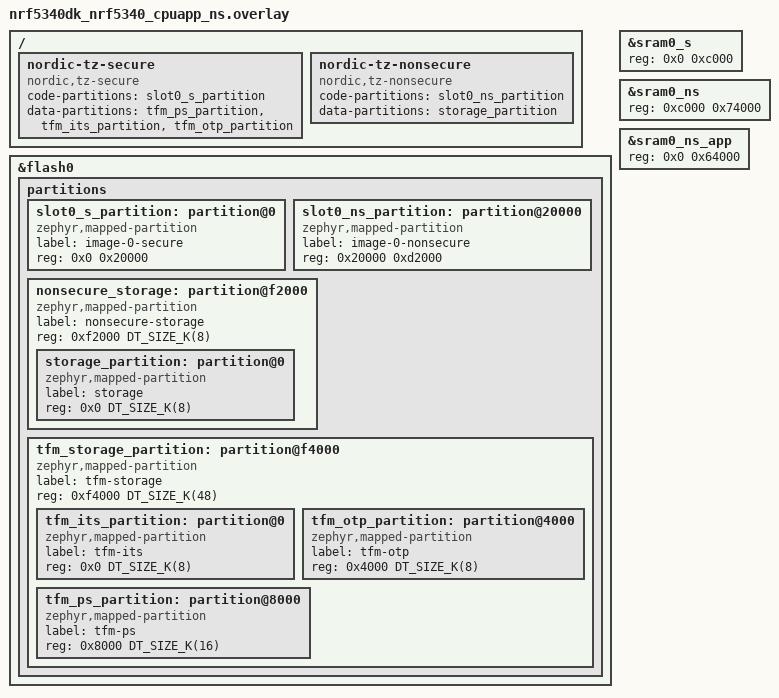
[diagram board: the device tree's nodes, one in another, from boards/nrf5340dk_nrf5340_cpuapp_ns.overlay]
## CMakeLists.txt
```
#
# Copyright (c) 2021 Nordic Semiconductor
#
# SPDX-License-Identifier: LicenseRef-Nordic-5-Clause
#

cmake_minimum_required(VERSION 3.20.0)

find_package(Zephyr REQUIRED HINTS $ENV{ZEPHYR_BASE})
project(NONE)

target_sources(app  PRIVATE src/main.c)
```

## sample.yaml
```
sample:
  description: NFC Launch App sample
  name: NFC Launch App
tests:
  sample.nfc.launch_app:
    sysbuild: true
    build_only: true
    integration_platforms:
      - nrf52840dk/nrf52840
      - nrf5340dk/nrf5340/cpuapp
      - nrf5340dk/nrf5340/cpuapp/ns
      - nrf54h20dk/nrf54h20/cpuapp
      - nrf54l15dk/nrf54l05/cpuapp
      - nrf54l15dk/nrf54l10/cpuapp
      - nrf54l15dk/nrf54l15/cpuapp
      - nrf54lm20dk/nrf54lm20a/cpuapp
      - nrf7120dk/nrf7120/cpuapp
    platform_allow:
      - nrf52840dk/nrf52840
      - nrf52dk/nrf52832
      - nrf5340dk/nrf5340/cpuapp
      - nrf5340dk/nrf5340/cpuapp/ns
      - nrf54h20dk/nrf54h20/cpuapp
      - nrf54l15dk/nrf54l05/cpuapp
      - nrf54l15dk/nrf54l10/cpuapp
      - nrf54l15dk/nrf54l15/cpuapp
      - nrf54lm20dk/nrf54lm20a/cpuapp
      - nrf7120dk/nrf7120/cpuapp
    tags:
      - ci_build
      - sysbuild
      - ci_samples_nfc
```

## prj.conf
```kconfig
#
# Copyright (c) 2021 Nordic Semiconductor ASA
#
# SPDX-License-Identifier: LicenseRef-Nordic-5-Clause
#
CONFIG_NCS_SAMPLES_DEFAULTS=y

CONFIG_REBOOT=y
CONFIG_DK_LIBRARY=y

CONFIG_NFC_T2T_NRFXLIB=y

CONFIG_NFC_NDEF=y
CONFIG_NFC_NDEF_MSG=y
CONFIG_NFC_NDEF_RECORD=y
CONFIG_NFC_NDEF_URI_REC=y
CONFIG_NFC_NDEF_LAUNCHAPP_MSG=y
```

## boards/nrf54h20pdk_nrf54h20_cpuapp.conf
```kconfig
#
# Copyright (c) 2023 Nordic Semiconductor ASA
#
# SPDX-License-Identifier: LicenseRef-Nordic-5-Clause
#

CONFIG_SERIAL=y
CONFIG_CONSOLE=y
CONFIG_UART_CONSOLE=y
```

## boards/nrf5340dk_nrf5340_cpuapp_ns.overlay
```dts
/*
 * Copyright (c) 2026 Nordic Semiconductor ASA
 *
 * SPDX-License-Identifier: LicenseRef-Nordic-5-Clause
 */

/delete-node/ &boot_partition;
/delete-node/ &slot0_partition;
/delete-node/ &slot1_partition;
/delete-node/ &tfm_its_partition;
/delete-node/ &tfm_otp_partition;
/delete-node/ &tfm_ps_partition;
/delete-node/ &storage_partition;

&flash0 {
	partitions {
		slot0_s_partition: partition@0 {
			compatible = "zephyr,mapped-partition";
			label = "image-0-secure";
			reg = <0x0 0x20000>;
		};

		slot0_ns_partition: partition@20000 {
			compatible = "zephyr,mapped-partition";
			label = "image-0-nonsecure";
			reg = <0x20000 0xd2000>;
		};

		nonsecure_storage: partition@f2000 {
			compatible = "zephyr,mapped-partition";
			label = "nonsecure-storage";
			reg = <0xf2000 DT_SIZE_K(8)>;
			ranges = <0x0 0xf2000 DT_SIZE_K(8)>;
			#address-cells = <1>;
			#size-cells = <1>;

			storage_partition: partition@0 {
				compatible = "zephyr,mapped-partition";
				label = "storage";
				reg = <0x0 DT_SIZE_K(8)>;
			};
		};

		tfm_storage_partition: partition@f4000 {
			compatible = "zephyr,mapped-partition";
			label = "tfm-storage";
			reg = <0xf4000 DT_SIZE_K(48)>;
			ranges = <0x0 0xf4000 DT_SIZE_K(48)>;
			#address-cells = <1>;
			#size-cells = <1>;

			tfm_its_partition: partition@0 {
				compatible = "zephyr,mapped-partition";
				label = "tfm-its";
				reg = <0x0 DT_SIZE_K(8)>;
			};

			tfm_otp_partition: partition@4000 {
				compatible = "zephyr,mapped-partition";
				label = "tfm-otp";
				reg = <0x4000 DT_SIZE_K(8)>;
			};

			tfm_ps_partition: partition@8000 {
				compatible = "zephyr,mapped-partition";
				label = "tfm-ps";
				reg = <0x8000 DT_SIZE_K(16)>;
			};
		};
	};
};

&sram0_s {
	reg = <0x0 0xc000>;
};

&sram0_ns {
	reg = <0xc000 0x74000>;
	ranges = <0x0 0xc000 0x74000>;
};

&sram0_ns_app {
	reg = <0x0 0x64000>;
};

/ {
	/delete-node/ nordic-tz-secure;
	/delete-node/ nordic-tz-nonsecure;

	nordic-tz-secure {
		compatible = "nordic,tz-secure";
		code-partitions = <&slot0_s_partition>;
		data-partitions = <&tfm_ps_partition>,
				  <&tfm_its_partition>,
				  <&tfm_otp_partition>;
	};

	nordic-tz-nonsecure {
		compatible = "nordic,tz-nonsecure";
		code-partitions = <&slot0_ns_partition>;
		data-partitions = <&storage_partition>;
	};
};
```

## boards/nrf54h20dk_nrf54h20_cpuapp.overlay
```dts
/*
 * Copyright (c) 2024 Nordic Semiconductor ASA
 *
 * SPDX-License-Identifier: LicenseRef-Nordic-5-Clause
 */

&nfct {
	status = "okay";
	memory-regions = <&cpuapp_dma_region>;
};

&timer137 {
	status = "okay"
	prescaler = <0>;
}
```

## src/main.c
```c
/*
 * Copyright (c) 2021 Nordic Semiconductor ASA
 *
 * SPDX-License-Identifier: LicenseRef-Nordic-5-Clause
 */

#include <zephyr/kernel.h>
#include <zephyr/sys/reboot.h>

#include <nfc_t2t_lib.h>
#include <nfc/ndef/launchapp_msg.h>

#include <dk_buttons_and_leds.h>

#define NDEF_MSG_BUF_SIZE	256
#define NFC_FIELD_LED		DK_LED1

/** .. include_startingpoint_pkg_def_launchapp_rst */
/* Package: no.nordicsemi.android.nrftoolbox */
static const uint8_t android_pkg_name[] = {
	'n', 'o', '.', 'n', 'o', 'r', 'd', 'i', 'c', 's', 'e', 'm', 'i', '.', 'a', 'n', 'd', 'r',
	'o', 'i', 'd', '.', 'n', 'r', 'f', 't', 'o', 'o', 'l', 'b', 'o', 'x' };

/* URI nrf-toolbox://main/ */
static const uint8_t universal_link[] = {
	'n', 'r', 'f', '-', 't', 'o', 'o', 'l', 'b', 'o', 'x', ':', '/', '/', 'm', 'a', 'i', 'n',
	'/'};
/** .. include_endpoint_pkg_def_launchapp_rst */

/* Buffer used to hold an NFC NDEF message. */
static uint8_t ndef_msg_buf[NDEF_MSG_BUF_SIZE];


static void nfc_callback(void *context,
			 nfc_t2t_event_t event,
			 const uint8_t *data,
			 size_t data_length)
{
	ARG_UNUSED(context);
	ARG_UNUSED(data);
	ARG_UNUSED(data_length);

	switch (event) {
	case NFC_T2T_EVENT_FIELD_ON:
		dk_set_led_on(NFC_FIELD_LED);
		break;
	case NFC_T2T_EVENT_FIELD_OFF:
		dk_set_led_off(NFC_FIELD_LED);
		break;
	default:
		break;
	}
}

int main(void)
{
	int err;
	size_t len = sizeof(ndef_msg_buf);

	printk("Starting NFC Launch app sample\n");

	/* Configure LED-pins as outputs */
	err = dk_leds_init();
	if (err) {
		printk("Cannot init LEDs!\n");
		goto fail;
	}

	/* Set up NFC */
	err = nfc_t2t_setup(nfc_callback, NULL);
	if (err) {
		printk("Cannot setup NFC T2T library!\n");
		goto fail;
	}

	/* Encode launch app data  */
	err = nfc_launchapp_msg_encode(android_pkg_name,
				       sizeof(android_pkg_name),
				       universal_link,
				       sizeof(universal_link),
				       ndef_msg_buf,
				       &len);
	if (err) {
		printk("Cannot encode message!\n");
		goto fail;
	}

	/* Set created message as the NFC payload */
	err = nfc_t2t_payload_set(ndef_msg_buf, len);
	if (err) {
		printk("Cannot set payload!\n");
		goto fail;
	}

	/* Start sensing NFC field */
	err = nfc_t2t_emulation_start();
	if (err) {
		printk("Cannot start emulation!\n");
		goto fail;
	}

	printk("NFC configuration done\n");
	return 0;

fail:
#if CONFIG_REBOOT
	sys_reboot(SYS_REBOOT_COLD);
#endif /* CONFIG_REBOOT */

	return err;
}
```
